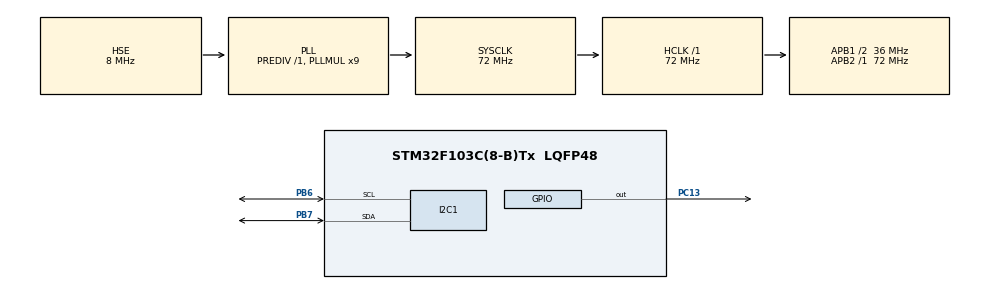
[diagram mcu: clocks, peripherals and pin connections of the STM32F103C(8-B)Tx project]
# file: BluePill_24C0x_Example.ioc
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I2C1.I2C_Mode=I2C_Fast
Mcu.Family=STM32F1
Mcu.Name=STM32F103C(8-B)Tx
Mcu.Package=LQFP48
NVIC.PriorityGroup=NVIC_PRIORITYGROUP_4
PA13.Mode=Serial_Wire
PA13.Signal=SYS_JTMS-SWDIO
PA14.Mode=Serial_Wire
PA14.Signal=SYS_JTCK-SWCLK
PB6.Mode=I2C
PB6.Signal=I2C1_SCL
PB7.Mode=I2C
PB7.Signal=I2C1_SDA
PC13-TAMPER-RTC.PinState=GPIO_PIN_SET
PC13-TAMPER-RTC.Signal=GPIO_Output
PD0-OSC_IN.Mode=HSE-External-Oscillator
PD0-OSC_IN.Signal=RCC_OSC_IN
PD1-OSC_OUT.Mode=HSE-External-Oscillator
PD1-OSC_OUT.Signal=RCC_OSC_OUT
ProjectManager.HeapSize=0x200
ProjectManager.StackSize=0x400
ProjectManager.TargetToolchain=STM32CubeIDE
RCC.AHBFreq_Value=72000000
RCC.APB1CLKDivider=RCC_HCLK_DIV2
RCC.APB1Freq_Value=36000000
RCC.APB1TimFreq_Value=72000000
RCC.APB2Freq_Value=72000000
RCC.APB2TimFreq_Value=72000000
RCC.HCLKFreq_Value=72000000
RCC.PLLMUL=RCC_PLL_MUL9
RCC.PLLSourceVirtual=RCC_PLLSOURCE_HSE
RCC.SYSCLKFreq_VALUE=72000000
RCC.SYSCLKSource=RCC_SYSCLKSOURCE_PLLCLK
RCC.USBFreq_Value=72000000
board=custom

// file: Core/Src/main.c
/* USER CODE BEGIN Header */
/**
  ******************************************************************************
  * @file           : main.c
  * @brief          : Main program body
  ******************************************************************************
  * @attention
  *
  * Copyright (c) 2025 STMicroelectronics.
  * All rights reserved.
  *
  * This software is licensed under terms that can be found in the LICENSE file
  * in the root directory of this software component.
  * If no LICENSE file comes with this software, it is provided AS-IS.
  *
  ******************************************************************************
  */
/* USER CODE END Header */
#include "main.h"

/* USER CODE BEGIN Includes */
#include <stdio.h>
/* USER CODE END Includes */

I2C_HandleTypeDef hi2c1;

void SystemClock_Config(void);
static void MX_GPIO_Init(void);
static void MX_I2C1_Init(void);

/* USER CODE BEGIN 0 */

typedef struct {
    uint8_t ADDR;
    I2C_HandleTypeDef* _i2c;
    uint16_t size;
} _24Cx;

HAL_StatusTypeDef writeEEPROM(_24Cx eeprom, uint8_t address, const void* data, uint16_t size)
{
    if (address + size > eeprom.size) {
        return HAL_ERROR;
    }
    HAL_StatusTypeDef status = HAL_I2C_Mem_Write(
        eeprom._i2c,
        (eeprom.ADDR << 1),
        address,
        I2C_MEMADD_SIZE_8BIT,
        (uint8_t*)data,
        size,
        HAL_MAX_DELAY
    );
    if (status == HAL_OK) {
        HAL_Delay(5); // EEPROM write cycle time
    }
    return status;
}

HAL_StatusTypeDef readEEPROM(_24Cx eeprom, uint8_t address, void* data, uint16_t size)
{
    if (address + size > eeprom.size) {
        return HAL_ERROR;
    }
    return HAL_I2C_Mem_Read(
        eeprom._i2c,
        (eeprom.ADDR << 1),
        address,
        I2C_MEMADD_SIZE_8BIT,
        (uint8_t*)data,
        size,
        HAL_MAX_DELAY
    );
}

void checkEEPROMConnection(_24Cx eeprom)
{
    HAL_StatusTypeDef result;
    uint8_t readData = 0x00;

    result = HAL_I2C_Mem_Read(eeprom._i2c, (eeprom.ADDR << 1), 0x00, I2C_MEMADD_SIZE_8BIT, &readData, 1, HAL_MAX_DELAY);

    if (result == HAL_OK)
    {
        printf("EEPROM baglantisi basarili! Okunan veri: 0x%02X\r\n", readData);
    }
    else
    {
        printf("EEPROM baglantisi basarisiz!\r\n");
    }
}

_24Cx eeprom = { .ADDR = 0x50, ._i2c = &hi2c1, .size = 128};
/* USER CODE END 0 */

int main(void)
{

  /* MCU Configuration--------------------------------------------------------*/

  /* Reset of all peripherals, Initializes the Flash interface and the Systick. */
  HAL_Init();

  /* Configure the system clock */
  SystemClock_Config();

  /* Initialize all configured peripherals */
  MX_GPIO_Init();
  MX_I2C1_Init();
  /* USER CODE BEGIN 2 */

  checkEEPROMConnection(eeprom);

  // Örnek veri tipleri
    uint8_t u8_data = 0xAA;
    int16_t i16_data = -1234;
    uint32_t u32_data = 12345678;
    float f_data = 3.14159;

    // EEPROM'a yazma
    uint8_t address = 0x00; // Başlangıç adresi
    HAL_StatusTypeDef status;

    // uint8_t yaz
    status = writeEEPROM(eeprom, address, &u8_data, sizeof(u8_data));
    if (status != HAL_OK) printf("uint8_t yazma hatası: %d\n", status);
    address += sizeof(u8_data);

    // int16_t yaz
    status = writeEEPROM(eeprom, address, &i16_data, sizeof(i16_data));
    if (status != HAL_OK) printf("int16_t yazma hatası: %d\n", status);
    address += sizeof(i16_data);

    // uint32_t yaz
    status = writeEEPROM(eeprom, address, &u32_data, sizeof(u32_data));
    if (status != HAL_OK) printf("uint32_t yazma hatası: %d\n", status);
    address += sizeof(u32_data);

    // float yaz
    status = writeEEPROM(eeprom, address, &f_data, sizeof(f_data));
    if (status != HAL_OK) printf("float yazma hatası: %d\n", status);
    address += sizeof(f_data);

    // EEPROM'dan okuma
    address = 0x00; // Adresi sıfırla
    uint8_t u8_read;
    int16_t i16_read;
    uint32_t u32_read;
    float f_read;

    // uint8_t oku
    status = readEEPROM(eeprom, address, &u8_read, sizeof(u8_read));
    if (status == HAL_OK) printf("Okunan uint8_t: 0x%02X\n", u8_read);
    else printf("uint8_t okuma hatası: %d\n", status);
    address += sizeof(u8_read);

    // int16_t oku
    status = readEEPROM(eeprom, address, &i16_read, sizeof(i16_read));
    if (status == HAL_OK) printf("Okunan int16_t: %d\n", i16_read);
    else printf("int16_t okuma hatası: %d\n", status);
    address += sizeof(i16_read);

    // uint32_t oku
    status = readEEPROM(eeprom, address, &u32_read, sizeof(u32_read));
    if (status == HAL_OK) printf("Okunan uint32_t: %lu \n", u32_read);
    else printf("uint32_t okuma hatası: %d\n", status);
    address += sizeof(u32_read);

    // float oku
    status = readEEPROM(eeprom, address, &f_read, sizeof(f_read));
    if (status == HAL_OK) printf("Okunan float: %.5f\n", f_read);
    else printf("float okuma hatası: %d\n", status);
  /* USER CODE END 2 */

  /* Infinite loop */
  while (1)
  {

  }
}

void SystemClock_Config(void)
{
  RCC_OscInitTypeDef RCC_OscInitStruct = {0};
  RCC_ClkInitTypeDef RCC_ClkInitStruct = {0};

  /** Initializes the RCC Oscillators according to the specified parameters
  * in the RCC_OscInitTypeDef structure.
  */
  RCC_OscInitStruct.OscillatorType = RCC_OSCILLATORTYPE_HSE;
  RCC_OscInitStruct.HSEState = RCC_HSE_ON;
  RCC_OscInitStruct.HSEPredivValue = RCC_HSE_PREDIV_DIV1;
  RCC_OscInitStruct.HSIState = RCC_HSI_ON;
  RCC_OscInitStruct.PLL.PLLState = RCC_PLL_ON;
  RCC_OscInitStruct.PLL.PLLSource = RCC_PLLSOURCE_HSE;
  RCC_OscInitStruct.PLL.PLLMUL = RCC_PLL_MUL9;
  if (HAL_RCC_OscConfig(&RCC_OscInitStruct) != HAL_OK)
  {
    Error_Handler();
  }

  /** Initializes the CPU, AHB and APB buses clocks
  */
  RCC_ClkInitStruct.ClockType = RCC_CLOCKTYPE_HCLK|RCC_CLOCKTYPE_SYSCLK
                              |RCC_CLOCKTYPE_PCLK1|RCC_CLOCKTYPE_PCLK2;
  RCC_ClkInitStruct.SYSCLKSource = RCC_SYSCLKSOURCE_PLLCLK;
  RCC_ClkInitStruct.AHBCLKDivider = RCC_SYSCLK_DIV1;
  RCC_ClkInitStruct.APB1CLKDivider = RCC_HCLK_DIV2;
  RCC_ClkInitStruct.APB2CLKDivider = RCC_HCLK_DIV1;

  if (HAL_RCC_ClockConfig(&RCC_ClkInitStruct, FLASH_LATENCY_2) != HAL_OK)
  {
    Error_Handler();
  }
}

static void MX_I2C1_Init(void)
{

  hi2c1.Instance = I2C1;
  hi2c1.Init.ClockSpeed = 400000;
  hi2c1.Init.DutyCycle = I2C_DUTYCYCLE_2;
  hi2c1.Init.OwnAddress1 = 0;
  hi2c1.Init.AddressingMode = I2C_ADDRESSINGMODE_7BIT;
  hi2c1.Init.DualAddressMode = I2C_DUALADDRESS_DISABLE;
  hi2c1.Init.OwnAddress2 = 0;
  hi2c1.Init.GeneralCallMode = I2C_GENERALCALL_DISABLE;
  hi2c1.Init.NoStretchMode = I2C_NOSTRETCH_DISABLE;
  if (HAL_I2C_Init(&hi2c1) != HAL_OK)
  {
    Error_Handler();
  }

}

static void MX_GPIO_Init(void)
{
  GPIO_InitTypeDef GPIO_InitStruct = {0};

  /* GPIO Ports Clock Enable */
  __HAL_RCC_GPIOC_CLK_ENABLE();
  __HAL_RCC_GPIOD_CLK_ENABLE();
  __HAL_RCC_GPIOA_CLK_ENABLE();
  __HAL_RCC_GPIOB_CLK_ENABLE();

  /*Configure GPIO pin Output Level */
  HAL_GPIO_WritePin(GPIOC, GPIO_PIN_13, GPIO_PIN_SET);

  /*Configure GPIO pin : PC13 */
  GPIO_InitStruct.Pin = GPIO_PIN_13;
  GPIO_InitStruct.Mode = GPIO_MODE_OUTPUT_PP;
  GPIO_InitStruct.Pull = GPIO_NOPULL;
  GPIO_InitStruct.Speed = GPIO_SPEED_FREQ_LOW;
  HAL_GPIO_Init(GPIOC, &GPIO_InitStruct);

}

void Error_Handler(void)
{
  __disable_irq();
  while (1)
  {
  }
}
